# CS_367.0 register map
Vendor: Texas Instruments
Peripheral module from a debugger description file (folder msp430).
Registers are 16-bit, read-write, no defined reset value unless marked. A register's access mark holds for its fields unless they carry their own. Offsets are as the file gives them; lines under a group give offsets from that group; [hi:lo] are bit positions; {n}, {i} and the like mark numbered series; 'fields as' and 'values as' point back to an identical list; <NAME> marks a mode.

## CS
0x00 CSCTL0 — Clock System Control 0
  [15:8] CSKEY — CSKEY password
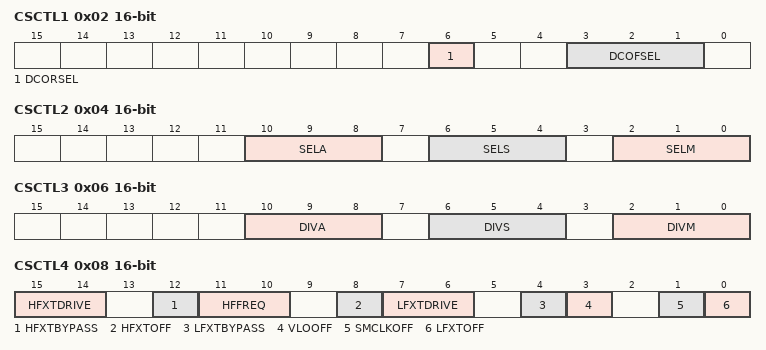
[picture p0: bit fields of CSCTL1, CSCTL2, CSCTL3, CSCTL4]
0x02 CSCTL1 — Clock System Control 1
  [6] DCORSEL — DCO range select
  [3:1] DCOFSEL — DCO frequency select
    0=If DCORSEL = 0: 1 MHz; If DCORSEL = 1: 1 MHz; 1=If DCORSEL = 0: 2.67 MHz; If DCORSEL = 1: 5.33 MHz; 2=If DCORSEL = 0: 3.33 MHz; If DCORSEL = 1: 6.67 MHz; 3=If DCORSEL = 0: 4 MHz; If DCORSEL = 1: 8 MHz; 4=If DCORSEL = 0: 5.33 MHz; If DCORSEL = 1: 16 MHz; 5=If DCORSEL = 0: 6.67 MHz; If DCORSEL = 1: 21 MHz; 6=If DCORSEL = 0: 8 MHz; If DCORSEL = 1: 24 MHz; 7=If DCORSEL = 0: Reserved. Defaults to 8. It is not recommended to use this setting; If DCORSEL = 1: Reserved. Defaults to 24. It is not recommended to use this setting
0x04 CSCTL2 — Clock System Control 2
  [10:8] SELA — Selects the ACLK source
    0=LFXTCLK (LFXTCLK when LFXT available, otherwise VLOCLK.); 1=VLOCLK; 2=LFMODCLK
  [6:4] SELS — Selects the SMCLK source
    0=LFXTCLK (LFXTCLK when LFXT available, otherwise VLOCLK.); 1=VLOCLK; 2=LFMODCLK; 3=DCOCLK; 4=MODCLK; 5=HFXTCLK (HFXTCLK when HFXT available, otherwise DCOCLK.)
  [2:0] SELM — Selects the MCLK source
    0=LFXTCLK (LFXTCLK when LFXT available, otherwise VLOCLK); 1=VLOCLK; 2=LFMODCLK; 3=DCOCLK; 4=MODCLK; 5=HFXTCLK (HFXTCLK when HFXT available, otherwise DCOCLK)
0x06 CSCTL3 — Clock System Control 3
  [all] fields
    0=1; 1=2; 2=4; 3=8; 4=16; 5=32
  [10:8] DIVA — ACLK source divider
  [6:4] DIVS — SMCLK source divider
  [2:0] DIVM — MCLK source divider
0x08 CSCTL4 — Clock System Control 4
  [15:14] HFXTDRIVE — HFXT oscillator current
    0=Lowest current consumption; 1=Increased drive strength HFXT oscillator; 2=Increased drive strength HFXT oscillator; 3=Maximum drive strength HFXT oscillator
  [12] HFXTBYPASS — HFXT bypass select
    0=HFXT sourced from external crystal; 1=HFXT sourced from external clock signal
  [11:10] HFFREQ — HFXT frequency selection
    0=0 to 4 MHz; 1=Greater than 4 MHz to 8 MHz; 2=Greater than 8 MHz to 16 MHz; 3=Greater than 16 MHz to 24 MHz
  [8] HFXTOFF — Turns off the HFXT oscillator
    0=HFXT is on if HFXT is selected via the port selection and HFXT is not in bypass mode of operation; 1=HFXT is off if it is not used as a source for ACLK, MCLK, or SMCLK
  [7:6] LFXTDRIVE — LFXT oscillator current
    0=Lowest drive strength and current consumption LFXT oscillator; 1=Increased drive strength LFXT oscillator; 2=Increased drive strength LFXT oscillator; 3=Maximum drive strength and maximum current consumption LFXT oscillator
  [4] LFXTBYPASS — LFXT bypass select
    0=LFXT sourced from external crystal; 1=LFXT sourced from external clock signal
  [3] VLOOFF
    0=VLO is on; 1=VLO is off if it is not used as a source for ACLK, MCLK, or SMCLK or if not used as a source for the RTC in LPM3.5
  [1] SMCLKOFF
    0=SMCLK on; 1=SMCLK off
  [0] LFXTOFF
    0=LFXT is on if LFXT is selected via the port selection and LFXT is not in bypass mode of operation; 1=LFXT is off if it is not used as a source for ACLK, MCLK, or SMCLK
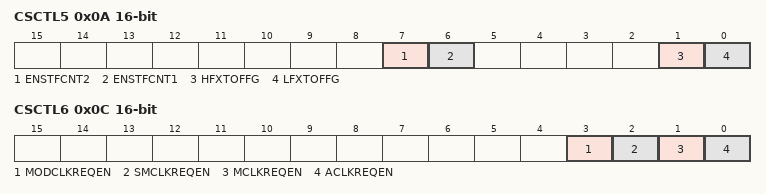
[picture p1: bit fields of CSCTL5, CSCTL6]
0x0A CSCTL5 — Clock System Control 5
  [7] ENSTFCNT2 — Enable start counter for HFXT
    0=DISABLE (Startup fault counter disabled. Counter is cleared.); 1=ENABLE (Startup fault counter enabled)
  [6] ENSTFCNT1 — Enable start counter for LFXT
    values as ENSTFCNT2
  [1] HFXTOFFG — HFXT oscillator fault flag
    0=No fault condition occurred after the last reset; 1=HFXT fault; an HFXT fault occurred after the last reset
  [0] LFXTOFFG — LFXT oscillator fault flag
    0=No fault condition occurred after the last reset; 1=LFXT fault; an LFXT fault occurred after the last reset
0x0C CSCTL6 — Clock System Control 6
  [3] MODCLKREQEN — MODCLK clock request enable
    0=DISABLE (MODCLK conditional requests are disabled); 1=ENABLE (MODCLK conditional requests are enabled)
  [2] SMCLKREQEN — SMCLK clock request enable
    0=DISABLE (SMCLK conditional requests are disabled); 1=ENABLE (SMCLK conditional requests are enabled)
  [1] MCLKREQEN — MCLK clock request enable
    0=DISABLE (MCLK conditional requests are disabled); 1=ENABLE (MCLK conditional requests are enabled)
  [0] ACLKREQEN — ACLK clock request enable
    0=DISABLE (ACLK conditional requests are disabled); 1=ENABLE (ACLK conditional requests are enabled)
